# ENCODER0_REG_DEBLOCKER_CORE_0 register map
Vendor: Texas Instruments
Peripheral module from a debugger description file (folder J7ES).
Registers are 32-bit, read-only, reset values left out (the file's numbers can be read two ways) unless marked. A register's access mark holds for its fields unless they carry their own. Offsets are as the file gives them; lines under a group give offsets from that group; [hi:lo] are bit positions; {n}, {i} and the like mark numbered series; 'fields as' and 'values as' point back to an identical list; <NAME> marks a mode.

## ENCODER0_REG_DEBLOCKER_CORE_0
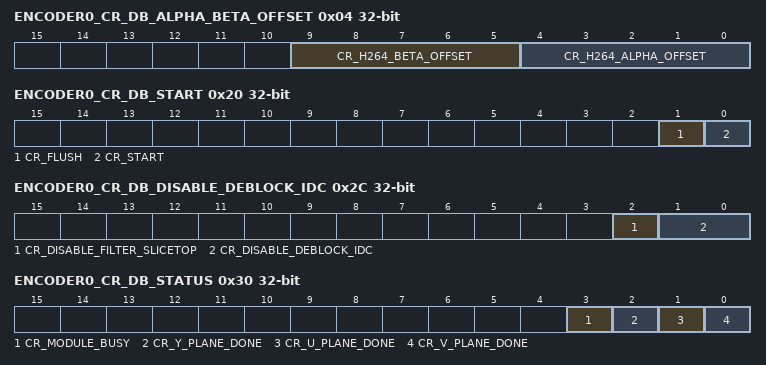
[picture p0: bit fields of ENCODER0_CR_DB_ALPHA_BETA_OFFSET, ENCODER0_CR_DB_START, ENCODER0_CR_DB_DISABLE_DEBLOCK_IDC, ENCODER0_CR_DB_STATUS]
0x04 ENCODER0_CR_DB_ALPHA_BETA_OFFSET access per field
  [9:5] CR_H264_BETA_OFFSET rw — FilterOffsetB
  [4:0] CR_H264_ALPHA_OFFSET rw — FilterOffsetA
0x08 ENCODER0_CR_DB_BUF_STATE
  [27] CR_BUSY — 0: Deblocking filter is not busy
0x0C ENCODER0_CR_DB_CMD_FIFO_SIG
  [31:0] CR_CMD_IN_SIGNATURE — Signature analysis register for commands into the deblocker
0x10 ENCODER0_CR_DB_INPUT_SIG
  [31:0] CR_DATA_IN_SIGNATURE — Signature analysis register for the data into the deblocker
0x14 ENCODER0_CR_DB_OUTPUT_SIG
  [31:0] CR_DATA_OUT_SIGNATURE — Signature analysis register for the data out of the deblocker
0x18 ENCODER0_CR_DB_DIAG
  [31:0] CR_DIAG — Deblocker diagnostics register [debug only]
0x1C ENCODER0_CR_DB_SIG_ADDR
  [31:0] CR_ADDR_OUT_SIGNATURE — Signature analysis register for the addresses output from the deblocker
0x20 ENCODER0_CR_DB_START access per field
  [1] CR_FLUSH rw — Pulse high to flush the deblocker pipeline to memory
  [0] CR_START rw — Pulse high to start processing a macroblock
0x24 ENCODER0_CR_DB_RESET access per field
  [0] CR_RESET rw — 0: Deblocker is not reset
0x2C ENCODER0_CR_DB_DISABLE_DEBLOCK_IDC access per field
  [2] CR_DISABLE_FILTER_SLICETOP rw — 0: normal
  [1:0] CR_DISABLE_DEBLOCK_IDC rw — 0x0: deblock all edges [except picture edges]
0x30 ENCODER0_CR_DB_STATUS
  [3] CR_MODULE_BUSY — 0: Deblocker is not busy
  [2] CR_Y_PLANE_DONE — Y plane processing is finished
  [1] CR_U_PLANE_DONE — U plane processing is finished
  [0] CR_V_PLANE_DONE — V plane processing is finished
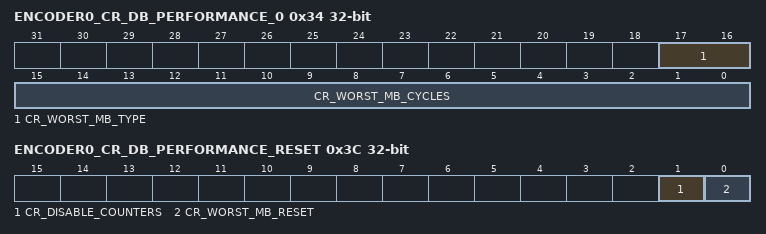
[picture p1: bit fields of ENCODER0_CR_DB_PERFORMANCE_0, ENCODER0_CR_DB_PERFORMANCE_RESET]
0x34 ENCODER0_CR_DB_PERFORMANCE_0
  [17:16] CR_WORST_MB_TYPE — The MB type of the worst MB.
  [15:0] CR_WORST_MB_CYCLES — The number of cycles taken to process the worst MB.
0x38 ENCODER0_CR_DB_PERFORMANCE_1
  [21:0] CR_WORST_MB_NUMBER — The linear MB number of the worst MB.
0x3C ENCODER0_CR_DB_PERFORMANCE_RESET access per field
  [1] CR_DISABLE_COUNTERS rw — The performance cycle counters should not be clocked when this bit is '1'
  [0] CR_WORST_MB_RESET rw — Writing this single bit with the value '1' clears both performance registers and resets the worst MB Num counter
